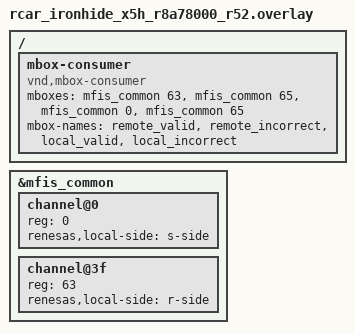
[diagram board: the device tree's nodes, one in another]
/*
 * Copyright (c) 2026 Renesas Electronics Corporation
 * SPDX-License-Identifier: Apache-2.0
 */

/ {
	mbox-consumer {
		compatible = "vnd,mbox-consumer";
		mboxes = <&mfis_common 63>, <&mfis_common 65>, <&mfis_common 0>, <&mfis_common 65>;
		mbox-names = "remote_valid", "remote_incorrect", "local_valid", "local_incorrect";
	};
};

&mfis_common {
	status = "okay";

	channel@0 {
		reg = <0>;
		renesas,local-side = "s-side";
	};

	channel@3f {
		reg = <63>;
		renesas,local-side = "r-side";
	};
};
